AUTOSAR XML (schema 00046)
package /EcuExtract
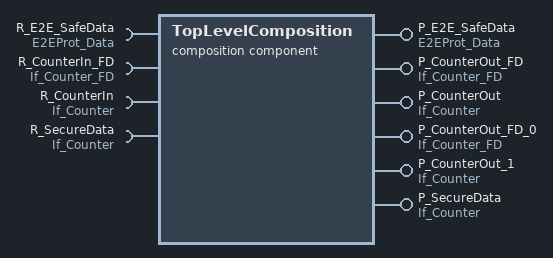
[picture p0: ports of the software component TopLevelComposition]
  composition sw component type TopLevelComposition
    provide port P_E2E_SafeData: provided-interface=E2EProt_Data
    require port R_E2E_SafeData: required-interface=E2EProt_Data
    provide port P_CounterOut_FD: provided-interface=If_Counter_FD
    provide port P_CounterOut: provided-interface=If_Counter
    provide port P_CounterOut_FD_0: provided-interface=If_Counter_FD
    require port R_CounterIn_FD: required-interface=If_Counter_FD
    provide port P_CounterOut_1: provided-interface=If_Counter
    require port R_CounterIn: required-interface=If_Counter
    provide port P_SecureData: provided-interface=If_Counter
    require port R_SecureData: required-interface=If_Counter
    17 x component:
      BswM_Prototype: type=BswM
      ComM_Prototype: type=ComM
      Dcm_Prototype: type=Dcm
      Dem_Prototype: type=Dem
      DevelopmentErrorTracer_Prototype: type=DevelopmentErrorTracer
      NvM_Prototype: type=NvM
      SWC_E2ESafety: type=SWC_E2ESafety
      SWC_SPI_Prototype: type=SWC_SPI
      SecOC_Prototype: type=SecOC
      SWC_AppStateHandler: type=SWC_AppStateHandler
      SWC_CyclicCounter: type=SWC_CyclicCounter
      SWC_IoHwAbs: type=SWC_IoHwAbs
      SWC_ModifyEcho: type=SWC_ModifyEcho
      ServiceSwComponentDcm: type=ServiceSwComponentDcm
      SWC_Secured: type=SWC_Secured
      ServiceSwComponentSecOC: type=ServiceSwComponentSecOC
      ServiceSwComponentDem: type=ServiceSwComponentDem
    connect BswM_Prototype.BswM_ModeRequestPort_BswMRteModeRequestPort_AppStateMode -> SWC_AppStateHandler.AppStateRequest
    connect SWC_AppStateHandler.AppState -> BswM_Prototype.ModeNotificationPort_BswM_ModeReqPort_AppState
    connect BswM_Prototype.BswM_ModeSwitchPort_BswM_SwitchPort_Rte -> SWC_CyclicCounter.ModeSwitchPort_BSWM_COMBINEDACTION_BswMMode_PortInterfaces_BswMMode
    connect ServiceSwComponentDcm.SecurityAccess_Level_1 -> Dcm_Prototype.SecurityAccess_Level_1
    connect ServiceSwComponentDcm.SecurityAccess_Level_3 -> Dcm_Prototype.SecurityAccess_Level_3
    connect ServiceSwComponentDcm.ServiceRequestManufacturerNotification_DcmDslServiceRequestManufacturerNotification_0 -> Dcm_Prototype.ServiceRequestManufacturerNotification_DcmDslServiceRequestManufacturerNotification_0
    connect ServiceSwComponentDcm.ServiceRequestSupplierNotification_DcmDslServiceRequestSupplierNotification_0 -> Dcm_Prototype.ServiceRequestSupplierNotification_DcmDslServiceRequestSupplierNotification_0
    connect ServiceSwComponentDcm.RoutineServices_DIAGNOSTIC_LOOPBACK -> Dcm_Prototype.RoutineServices_DIAGNOSTIC_LOOPBACK
    connect ServiceSwComponentDcm.RoutineServices_DIAGNOSTIC_TRIGGER_DTC -> Dcm_Prototype.RoutineServices_DIAGNOSTIC_TRIGGER_DTC
    connect ServiceSwComponentDcm.InfotypeServices_Service09_VinMessageCount -> Dcm_Prototype.InfotypeServices_Service09_VinMessageCount
    connect ServiceSwComponentDcm.InfotypeServices_Service09_VehicleIdentificationNumber -> Dcm_Prototype.InfotypeServices_Service09_VehicleIdentificationNumber
    connect Dem_Prototype.Event_DTC_0x000001_Event -> ServiceSwComponentDcm.DTC_0x000001_Event
    connect Dem_Prototype.Event_Permanent_DTC -> ServiceSwComponentDcm.Permanent_DTC_Event
    connect Dem_Prototype.Event_DTC_0x000002_Event -> ServiceSwComponentDcm.DTC_0x000002_Event
    connect Dem_Prototype.Event_USER_DEFINE_MEMORY_Event -> ServiceSwComponentDcm.USER_DEFINE_MEMORY_Event
    connect ServiceSwComponentDem.CBReadData_DemExternalCSDataElementClass_Session -> Dem_Prototype.CBReadData_DemExternalCSDataElementClass_Session
    connect ServiceSwComponentDem.CBReadData_DemExternalCSDataElementClass_ExtDataRec_0x01 -> Dem_Prototype.CBReadData_DemExternalCSDataElementClass_ExtDataRec_0x01
    connect ServiceSwComponentDem.SetClearDTC_master -> Dem_Prototype.SetClearDTC_master
    connect DevelopmentErrorTracer_Prototype.DS_SWC_0 -> SWC_CyclicCounter.R_CyclicCounterDet
    connect NvM_Prototype.PS_NvM_BLOCK_voltage -> SWC_SPI_Prototype.PS_NvM_Block_voltage
    connect NvM_Prototype.PS_PersistentCounterValue -> SWC_CyclicCounter.PS_PersistentCounterValue
    delegate SWC_E2ESafety.P_E2E_SafeData <-> outer port P_E2E_SafeData
    delegate SWC_E2ESafety.R_E2E_SafeData <-> outer port R_E2E_SafeData
    connect SWC_IoHwAbs.Pp_AdcValue -> SWC_SPI_Prototype.Rp_AdcValue
    connect ServiceSwComponentSecOC.PS_RxFreshnessManagement -> SecOC_Prototype.PS_RxFreshnessManagement
    connect ServiceSwComponentSecOC.PS_TxFreshnessManagement -> SecOC_Prototype.PS_TxFreshnessManagement
    delegate SWC_CyclicCounter.P_CounterOut_FD <-> outer port P_CounterOut_FD
    connect SWC_CyclicCounter.P_EchoCalc_FD -> SWC_ModifyEcho.R_EchoResult_FD
    connect SWC_CyclicCounter.P_EchoCalc -> SWC_ModifyEcho.R_EchoResult
    connect SWC_ModifyEcho.P_SpecialRequest -> SWC_CyclicCounter.R_SpecialHandling
    connect SWC_IoHwAbs.P_MyLED -> SWC_CyclicCounter.R_MyLED
    delegate SWC_CyclicCounter.P_CounterOut <-> outer port P_CounterOut
    delegate SWC_ModifyEcho.P_EchoOut_FD <-> outer port P_CounterOut_FD_0
    delegate SWC_ModifyEcho.R_NewCounterIn_FD <-> outer port R_CounterIn_FD
    delegate SWC_ModifyEcho.P_EchoOut <-> outer port P_CounterOut_1
    delegate SWC_ModifyEcho.R_NewCounterIn <-> outer port R_CounterIn
    delegate SWC_Secured.P_SecuredData <-> outer port P_SecureData
    delegate SWC_Secured.R_SecuredData <-> outer port R_SecureData
  system ECU: category=ECU_EXTRACT, system-version=1.0.0
    10 x system mapping:
      DataMappings_P_E2E_SafeData: sender-receiver-to-signal-group-mapping{data-element=TopLevelCompositionPrototype.P_E2E_SafeData.E2EProt_Data, signal-group=sigGroup_E2EProt_DataOut, type-mapping=sender-rec-record-type-mapping=record-element-mappings=[{implementation-record-element=SafetyE2E_Data, system-signal=SysSig_E2EProt_DataOut}, {implementation-record-element=SafetyE2E_Data_CRC, system-signal=SysSig_E2EProt_DataOut_CRC}, {implementation-record-element=SafetyE2E_Data_SQC_Counter, system-signal=SysSig_E2EProt_DataOut_SQC_Counter}]}
      DataMappings_R_E2E_SafeData: sender-receiver-to-signal-group-mapping{data-element=TopLevelCompositionPrototype.R_E2E_SafeData.E2EProt_Data, signal-group=sigGroup_E2EProt_DataIn, type-mapping=sender-rec-record-type-mapping=record-element-mappings=[{implementation-record-element=SafetyE2E_Data, system-signal=SysSig_E2EProt_DataIn}, {implementation-record-element=SafetyE2E_Data_CRC, system-signal=SysSig_E2EProt_DataIn_CRC}, {implementation-record-element=SafetyE2E_Data_SQC_Counter, system-signal=SysSig_E2EProt_DataIn_SQC_Counter}]}
      DataMappings_P_CounterOut_FD: sender-receiver-to-signal-mapping{data-element=TopLevelCompositionPrototype.P_CounterOut_FD.CounterValue_FD, system-signal=CounterOut_CAN_FD}
      DataMappings_P_CounterOut: sender-receiver-to-signal-mapping{data-element=TopLevelCompositionPrototype.P_CounterOut.CounterValue, system-signal=CounterOut}
      DataMappings_P_CounterOut_FD_0: sender-receiver-to-signal-mapping{data-element=TopLevelCompositionPrototype.P_CounterOut_FD_0.CounterValue_FD, system-signal=CounterOut_CAN_FD}
      DataMappings_R_CounterIn_FD: sender-receiver-to-signal-mapping{data-element=TopLevelCompositionPrototype.R_CounterIn_FD.CounterValue_FD, system-signal=CounterIn_CAN_FD}
      DataMappings_P_CounterOut_1: sender-receiver-to-signal-mapping{data-element=TopLevelCompositionPrototype.P_CounterOut_1.CounterValue, system-signal=CounterOut}
      DataMappings_R_CounterIn: sender-receiver-to-signal-mapping{data-element=TopLevelCompositionPrototype.R_CounterIn.CounterValue, system-signal=CounterIn}
      DataMappings_P_SecureData
        data-mappings:
          data-element=TopLevelCompositionPrototype.P_SecureData.CounterValue, system-signal=SecuredDataOut
          data-element=TopLevelCompositionPrototype.P_SecureData.CounterValue, system-signal=SecuredDataIn
      DataMappings_R_SecureData
        data-mappings:
          data-element=TopLevelCompositionPrototype.R_SecureData.CounterValue, system-signal=SecuredDataIn
          data-element=TopLevelCompositionPrototype.R_SecureData.CounterValue, system-signal=SecuredDataOut
    root-software-compositions:
      root sw composition prototype TopLevelCompositionPrototype: flat-map=FlatMap, software-composition=TopLevelComposition
  flat map FlatMap
    137 x flat instance descriptor:
      BswM_Prototype_0: upstream-reference=TopLevelComposition.BswM_Prototype, ecu-extract-reference=TopLevelCompositionPrototype.BswM_Prototype
      BswM_ModeSwitchPort_BswM_SwitchPort_Rte_1: upstream-reference=TopLevelComposition.BswM_Prototype.BswM_ModeSwitchPort_BswM_SwitchPort_Rte, ecu-extract-reference=TopLevelCompositionPrototype.BswM_Prototype.BswM_ModeSwitchPort_BswM_SwitchPort_Rte
      BswM_ModeRequestPort_BswMRteModeRequestPort_AppStateMode_2: upstream-reference=TopLevelComposition.BswM_Prototype.BswM_ModeRequestPort_BswMRteModeRequestPort_AppStateMode, ecu-extract-reference=TopLevelCompositionPrototype.BswM_Prototype.BswM_ModeRequestPort_BswMRteModeRequestPort_AppStateMode
      If_AppStateRequestMode_3: upstream-reference=TopLevelComposition.BswM_Prototype.BswM_ModeRequestPort_BswMRteModeRequestPort_AppStateMode.If_AppStateRequestMode, ecu-extract-reference=TopLevelCompositionPrototype.BswM_Prototype.BswM_ModeRequestPort_BswMRteModeRequestPort_AppStateMode.If_AppStateRequestMode
      ModeNotificationPort_BswM_ModeReqPort_AppState_4: upstream-reference=TopLevelComposition.BswM_Prototype.ModeNotificationPort_BswM_ModeReqPort_AppState, ecu-extract-reference=TopLevelCompositionPrototype.BswM_Prototype.ModeNotificationPort_BswM_ModeReqPort_AppState
      ComM_Prototype_5: upstream-reference=TopLevelComposition.ComM_Prototype, ecu-extract-reference=TopLevelCompositionPrototype.ComM_Prototype
      UM_ComMUser_0_6: upstream-reference=TopLevelComposition.ComM_Prototype.UM_ComMUser_0, ecu-extract-reference=TopLevelCompositionPrototype.ComM_Prototype.UM_ComMUser_0
      UR_ComMUser_0_7: upstream-reference=TopLevelComposition.ComM_Prototype.UR_ComMUser_0, ecu-extract-reference=TopLevelCompositionPrototype.ComM_Prototype.UR_ComMUser_0
      Dcm_Prototype_8: upstream-reference=TopLevelComposition.Dcm_Prototype, ecu-extract-reference=TopLevelCompositionPrototype.Dcm_Prototype
      DCMServices_9: upstream-reference=TopLevelComposition.Dcm_Prototype.DCMServices, ecu-extract-reference=TopLevelCompositionPrototype.Dcm_Prototype.DCMServices
      DCM_Roe_DcmDspRoeEvent_10: upstream-reference=TopLevelComposition.Dcm_Prototype.DCM_Roe_DcmDspRoeEvent, ecu-extract-reference=TopLevelCompositionPrototype.Dcm_Prototype.DCM_Roe_DcmDspRoeEvent
      SecurityAccess_Level_1_11: upstream-reference=TopLevelComposition.Dcm_Prototype.SecurityAccess_Level_1, ecu-extract-reference=TopLevelCompositionPrototype.Dcm_Prototype.SecurityAccess_Level_1
      SecurityAccess_Level_3_12: upstream-reference=TopLevelComposition.Dcm_Prototype.SecurityAccess_Level_3, ecu-extract-reference=TopLevelCompositionPrototype.Dcm_Prototype.SecurityAccess_Level_3
      ServiceRequestManufacturerNotification_DcmDslServiceRequestManufacturerNotification_0_13: upstream-reference=TopLevelComposition.Dcm_Prototype.ServiceRequestManufacturerNotification_DcmDslServiceRequestManufacturerNotification_0, ecu-extract-reference=TopLevelCompositionPrototype.Dcm_Prototype.ServiceRequestManufacturerNotification_DcmDslServiceRequestManufacturerNotification_0
      ServiceRequestSupplierNotification_DcmDslServiceRequestSupplierNotification_0_14: upstream-reference=TopLevelComposition.Dcm_Prototype.ServiceRequestSupplierNotification_DcmDslServiceRequestSupplierNotification_0, ecu-extract-reference=TopLevelCompositionPrototype.Dcm_Prototype.ServiceRequestSupplierNotification_DcmDslServiceRequestSupplierNotification_0
      RoutineServices_DIAGNOSTIC_LOOPBACK_15: upstream-reference=TopLevelComposition.Dcm_Prototype.RoutineServices_DIAGNOSTIC_LOOPBACK, ecu-extract-reference=TopLevelCompositionPrototype.Dcm_Prototype.RoutineServices_DIAGNOSTIC_LOOPBACK
      RoutineServices_DIAGNOSTIC_TRIGGER_DTC_16: upstream-reference=TopLevelComposition.Dcm_Prototype.RoutineServices_DIAGNOSTIC_TRIGGER_DTC, ecu-extract-reference=TopLevelCompositionPrototype.Dcm_Prototype.RoutineServices_DIAGNOSTIC_TRIGGER_DTC
      InfotypeServices_Service09_VinMessageCount_17: upstream-reference=TopLevelComposition.Dcm_Prototype.InfotypeServices_Service09_VinMessageCount, ecu-extract-reference=TopLevelCompositionPrototype.Dcm_Prototype.InfotypeServices_Service09_VinMessageCount
      InfotypeServices_Service09_VehicleIdentificationNumber_18: upstream-reference=TopLevelComposition.Dcm_Prototype.InfotypeServices_Service09_VehicleIdentificationNumber, ecu-extract-reference=TopLevelCompositionPrototype.Dcm_Prototype.InfotypeServices_Service09_VehicleIdentificationNumber
      Dem_Prototype_19: upstream-reference=TopLevelComposition.Dem_Prototype, ecu-extract-reference=TopLevelCompositionPrototype.Dem_Prototype
      Event_DTC_0x000001_Event_20: upstream-reference=TopLevelComposition.Dem_Prototype.Event_DTC_0x000001_Event, ecu-extract-reference=TopLevelCompositionPrototype.Dem_Prototype.Event_DTC_0x000001_Event
      EvtInfo_DTC_0x000001_Event_21: upstream-reference=TopLevelComposition.Dem_Prototype.EvtInfo_DTC_0x000001_Event, ecu-extract-reference=TopLevelCompositionPrototype.Dem_Prototype.EvtInfo_DTC_0x000001_Event
      Event_Permanent_DTC_22: upstream-reference=TopLevelComposition.Dem_Prototype.Event_Permanent_DTC, ecu-extract-reference=TopLevelCompositionPrototype.Dem_Prototype.Event_Permanent_DTC
      EvtInfo_Permanent_DTC_23: upstream-reference=TopLevelComposition.Dem_Prototype.EvtInfo_Permanent_DTC, ecu-extract-reference=TopLevelCompositionPrototype.Dem_Prototype.EvtInfo_Permanent_DTC
      EvtInfo_CANSM_E_BUS_OFF_0_24: upstream-reference=TopLevelComposition.Dem_Prototype.EvtInfo_CANSM_E_BUS_OFF_0, ecu-extract-reference=TopLevelCompositionPrototype.Dem_Prototype.EvtInfo_CANSM_E_BUS_OFF_0
      EvtInfo_WDGM_E_MONITORING_25: upstream-reference=TopLevelComposition.Dem_Prototype.EvtInfo_WDGM_E_MONITORING, ecu-extract-reference=TopLevelCompositionPrototype.Dem_Prototype.EvtInfo_WDGM_E_MONITORING
      EvtInfo_WDGM_E_SET_MODE_26: upstream-reference=TopLevelComposition.Dem_Prototype.EvtInfo_WDGM_E_SET_MODE, ecu-extract-reference=TopLevelCompositionPrototype.Dem_Prototype.EvtInfo_WDGM_E_SET_MODE
      EvtInfo_WDGM_E_DATA_CORRUPTION_27: upstream-reference=TopLevelComposition.Dem_Prototype.EvtInfo_WDGM_E_DATA_CORRUPTION, ecu-extract-reference=TopLevelCompositionPrototype.Dem_Prototype.EvtInfo_WDGM_E_DATA_CORRUPTION
      EvtInfo_ECUM_E_RAM_CHECK_FAILED_28: upstream-reference=TopLevelComposition.Dem_Prototype.EvtInfo_ECUM_E_RAM_CHECK_FAILED, ecu-extract-reference=TopLevelCompositionPrototype.Dem_Prototype.EvtInfo_ECUM_E_RAM_CHECK_FAILED
      EvtInfo_MCU_E_CLOCK_FAILURE_29: upstream-reference=TopLevelComposition.Dem_Prototype.EvtInfo_MCU_E_CLOCK_FAILURE, ecu-extract-reference=TopLevelCompositionPrototype.Dem_Prototype.EvtInfo_MCU_E_CLOCK_FAILURE
      EvtInfo_WDGM_E_MF_TIMINGVIOLATION_30: upstream-reference=TopLevelComposition.Dem_Prototype.EvtInfo_WDGM_E_MF_TIMINGVIOLATION, ecu-extract-reference=TopLevelCompositionPrototype.Dem_Prototype.EvtInfo_WDGM_E_MF_TIMINGVIOLATION
      Event_DTC_0x000002_Event_31: upstream-reference=TopLevelComposition.Dem_Prototype.Event_DTC_0x000002_Event, ecu-extract-reference=TopLevelCompositionPrototype.Dem_Prototype.Event_DTC_0x000002_Event
      EvtInfo_DTC_0x000002_Event_32: upstream-reference=TopLevelComposition.Dem_Prototype.EvtInfo_DTC_0x000002_Event, ecu-extract-reference=TopLevelCompositionPrototype.Dem_Prototype.EvtInfo_DTC_0x000002_Event
      Event_USER_DEFINE_MEMORY_Event_33: upstream-reference=TopLevelComposition.Dem_Prototype.Event_USER_DEFINE_MEMORY_Event, ecu-extract-reference=TopLevelCompositionPrototype.Dem_Prototype.Event_USER_DEFINE_MEMORY_Event
      EvtInfo_USER_DEFINE_MEMORY_Event_34: upstream-reference=TopLevelComposition.Dem_Prototype.EvtInfo_USER_DEFINE_MEMORY_Event, ecu-extract-reference=TopLevelCompositionPrototype.Dem_Prototype.EvtInfo_USER_DEFINE_MEMORY_Event
      EvtInfo_MCU_E_TIMEOUT_FAILURE_35: upstream-reference=TopLevelComposition.Dem_Prototype.EvtInfo_MCU_E_TIMEOUT_FAILURE, ecu-extract-reference=TopLevelCompositionPrototype.Dem_Prototype.EvtInfo_MCU_E_TIMEOUT_FAILURE
      EvtInfo_MCU_E_INVALIDFXOSC_CONFIG_36: upstream-reference=TopLevelComposition.Dem_Prototype.EvtInfo_MCU_E_INVALIDFXOSC_CONFIG, ecu-extract-reference=TopLevelCompositionPrototype.Dem_Prototype.EvtInfo_MCU_E_INVALIDFXOSC_CONFIG
      EvtInfo_MCU_E_CLOCKMUXSWITCH_FAILURE_37: upstream-reference=TopLevelComposition.Dem_Prototype.EvtInfo_MCU_E_CLOCKMUXSWITCH_FAILURE, ecu-extract-reference=TopLevelCompositionPrototype.Dem_Prototype.EvtInfo_MCU_E_CLOCKMUXSWITCH_FAILURE
      EvtInfo_SPI_E_HARDWARE_ERROR_38: upstream-reference=TopLevelComposition.Dem_Prototype.EvtInfo_SPI_E_HARDWARE_ERROR, ecu-extract-reference=TopLevelCompositionPrototype.Dem_Prototype.EvtInfo_SPI_E_HARDWARE_ERROR
      GeneralEvtInfo_39: upstream-reference=TopLevelComposition.Dem_Prototype.GeneralEvtInfo, ecu-extract-reference=TopLevelCompositionPrototype.Dem_Prototype.GeneralEvtInfo
      OpCycle_DEM_OPCYC_IGNITION_40: upstream-reference=TopLevelComposition.Dem_Prototype.OpCycle_DEM_OPCYC_IGNITION, ecu-extract-reference=TopLevelCompositionPrototype.Dem_Prototype.OpCycle_DEM_OPCYC_IGNITION
      OpCycle_DEM_OPCYC_OBD_DCY_41: upstream-reference=TopLevelComposition.Dem_Prototype.OpCycle_DEM_OPCYC_OBD_DCY, ecu-extract-reference=TopLevelCompositionPrototype.Dem_Prototype.OpCycle_DEM_OPCYC_OBD_DCY
      OpCycle_DEM_OPCYC_POWER_42: upstream-reference=TopLevelComposition.Dem_Prototype.OpCycle_DEM_OPCYC_POWER, ecu-extract-reference=TopLevelCompositionPrototype.Dem_Prototype.OpCycle_DEM_OPCYC_POWER
      EnableCond_DEM_SL_ECU_LEVEL_43: upstream-reference=TopLevelComposition.Dem_Prototype.EnableCond_DEM_SL_ECU_LEVEL, ecu-extract-reference=TopLevelCompositionPrototype.Dem_Prototype.EnableCond_DEM_SL_ECU_LEVEL
      IndStatus_DEM_INDICATOR_0_44: upstream-reference=TopLevelComposition.Dem_Prototype.IndStatus_DEM_INDICATOR_0, ecu-extract-reference=TopLevelCompositionPrototype.Dem_Prototype.IndStatus_DEM_INDICATOR_0
      OverflowIndPrimaryMemory_45: upstream-reference=TopLevelComposition.Dem_Prototype.OverflowIndPrimaryMemory, ecu-extract-reference=TopLevelCompositionPrototype.Dem_Prototype.OverflowIndPrimaryMemory
      OverflowIndSecondaryMemory_46: upstream-reference=TopLevelComposition.Dem_Prototype.OverflowIndSecondaryMemory, ecu-extract-reference=TopLevelCompositionPrototype.Dem_Prototype.OverflowIndSecondaryMemory
      OverflowIndPermanentMemory_47: upstream-reference=TopLevelComposition.Dem_Prototype.OverflowIndPermanentMemory, ecu-extract-reference=TopLevelCompositionPrototype.Dem_Prototype.OverflowIndPermanentMemory
      ControlDTCSuppression_48: upstream-reference=TopLevelComposition.Dem_Prototype.ControlDTCSuppression, ecu-extract-reference=TopLevelCompositionPrototype.Dem_Prototype.ControlDTCSuppression
      CddIf_49: upstream-reference=TopLevelComposition.Dem_Prototype.CddIf, ecu-extract-reference=TopLevelCompositionPrototype.Dem_Prototype.CddIf
      PfcCycleQualified_50: upstream-reference=TopLevelComposition.Dem_Prototype.PfcCycleQualified, ecu-extract-reference=TopLevelCompositionPrototype.Dem_Prototype.PfcCycleQualified
      ResetReadiness_51: upstream-reference=TopLevelComposition.Dem_Prototype.ResetReadiness, ecu-extract-reference=TopLevelCompositionPrototype.Dem_Prototype.ResetReadiness
      PowerTakeOffStatus_52: upstream-reference=TopLevelComposition.Dem_Prototype.PowerTakeOffStatus, ecu-extract-reference=TopLevelCompositionPrototype.Dem_Prototype.PowerTakeOffStatus
      CBReadData_DemExternalCSDataElementClass_Session_53: upstream-reference=TopLevelComposition.Dem_Prototype.CBReadData_DemExternalCSDataElementClass_Session, ecu-extract-reference=TopLevelCompositionPrototype.Dem_Prototype.CBReadData_DemExternalCSDataElementClass_Session
      CBReadData_DemExternalCSDataElementClass_ExtDataRec_0x01_54: upstream-reference=TopLevelComposition.Dem_Prototype.CBReadData_DemExternalCSDataElementClass_ExtDataRec_0x01, ecu-extract-reference=TopLevelCompositionPrototype.Dem_Prototype.CBReadData_DemExternalCSDataElementClass_ExtDataRec_0x01
      SetClearDTC_master_55: upstream-reference=TopLevelComposition.Dem_Prototype.SetClearDTC_master, ecu-extract-reference=TopLevelCompositionPrototype.Dem_Prototype.SetClearDTC_master
      DevelopmentErrorTracer_Prototype_56: upstream-reference=TopLevelComposition.DevelopmentErrorTracer_Prototype, ecu-extract-reference=TopLevelCompositionPrototype.DevelopmentErrorTracer_Prototype
      DS_SWC_0_57: upstream-reference=TopLevelComposition.DevelopmentErrorTracer_Prototype.DS_SWC_0, ecu-extract-reference=TopLevelCompositionPrototype.DevelopmentErrorTracer_Prototype.DS_SWC_0
      NvM_Prototype_58: upstream-reference=TopLevelComposition.NvM_Prototype, ecu-extract-reference=TopLevelCompositionPrototype.NvM_Prototype
      PS_PersistentCounterValue_59: upstream-reference=TopLevelComposition.NvM_Prototype.PS_PersistentCounterValue, ecu-extract-reference=TopLevelCompositionPrototype.NvM_Prototype.PS_PersistentCounterValue
      PS_NvM_BLOCK_voltage_60: upstream-reference=TopLevelComposition.NvM_Prototype.PS_NvM_BLOCK_voltage, ecu-extract-reference=TopLevelCompositionPrototype.NvM_Prototype.PS_NvM_BLOCK_voltage
      SWC_E2ESafety_61: upstream-reference=TopLevelComposition.SWC_E2ESafety, ecu-extract-reference=TopLevelCompositionPrototype.SWC_E2ESafety
      P_E2E_SafeData_62: upstream-reference=TopLevelComposition.SWC_E2ESafety.P_E2E_SafeData, ecu-extract-reference=TopLevelCompositionPrototype.SWC_E2ESafety.P_E2E_SafeData
      E2EProt_Data_63: upstream-reference=TopLevelComposition.SWC_E2ESafety.P_E2E_SafeData.E2EProt_Data, ecu-extract-reference=TopLevelCompositionPrototype.SWC_E2ESafety.P_E2E_SafeData.E2EProt_Data
      R_E2E_SafeData_64: upstream-reference=TopLevelComposition.SWC_E2ESafety.R_E2E_SafeData, ecu-extract-reference=TopLevelCompositionPrototype.SWC_E2ESafety.R_E2E_SafeData
      E2EProt_Data_65: upstream-reference=TopLevelComposition.SWC_E2ESafety.R_E2E_SafeData.E2EProt_Data, ecu-extract-reference=TopLevelCompositionPrototype.SWC_E2ESafety.R_E2E_SafeData.E2EProt_Data
      SWC_SPI_Prototype_66: upstream-reference=TopLevelComposition.SWC_SPI_Prototype, ecu-extract-reference=TopLevelCompositionPrototype.SWC_SPI_Prototype
      PS_NvM_Block_voltage_67: upstream-reference=TopLevelComposition.SWC_SPI_Prototype.PS_NvM_Block_voltage, ecu-extract-reference=TopLevelCompositionPrototype.SWC_SPI_Prototype.PS_NvM_Block_voltage
      Rp_AdcValue_68: upstream-reference=TopLevelComposition.SWC_SPI_Prototype.Rp_AdcValue, ecu-extract-reference=TopLevelCompositionPrototype.SWC_SPI_Prototype.Rp_AdcValue
      ArgData_69: upstream-reference=TopLevelComposition.SWC_SPI_Prototype.Rp_AdcValue.ArgData, ecu-extract-reference=TopLevelCompositionPrototype.SWC_SPI_Prototype.Rp_AdcValue.ArgData
      SecOC_Prototype_70: upstream-reference=TopLevelComposition.SecOC_Prototype, ecu-extract-reference=TopLevelCompositionPrototype.SecOC_Prototype
      PS_RxFreshnessManagement_71: upstream-reference=TopLevelComposition.SecOC_Prototype.PS_RxFreshnessManagement, ecu-extract-reference=TopLevelCompositionPrototype.SecOC_Prototype.PS_RxFreshnessManagement
      PS_VerifyStatusConfiguration_72: upstream-reference=TopLevelComposition.SecOC_Prototype.PS_VerifyStatusConfiguration, ecu-extract-reference=TopLevelCompositionPrototype.SecOC_Prototype.PS_VerifyStatusConfiguration
      PS_TxFreshnessManagement_73: upstream-reference=TopLevelComposition.SecOC_Prototype.PS_TxFreshnessManagement, ecu-extract-reference=TopLevelCompositionPrototype.SecOC_Prototype.PS_TxFreshnessManagement
      SWC_AppStateHandler_74: upstream-reference=TopLevelComposition.SWC_AppStateHandler, ecu-extract-reference=TopLevelCompositionPrototype.SWC_AppStateHandler
      AppState_75: upstream-reference=TopLevelComposition.SWC_AppStateHandler.AppState, ecu-extract-reference=TopLevelCompositionPrototype.SWC_AppStateHandler.AppState
      AppStateRequest_76: upstream-reference=TopLevelComposition.SWC_AppStateHandler.AppStateRequest, ecu-extract-reference=TopLevelCompositionPrototype.SWC_AppStateHandler.AppStateRequest
      If_AppStateRequestMode_77: upstream-reference=TopLevelComposition.SWC_AppStateHandler.AppStateRequest.If_AppStateRequestMode, ecu-extract-reference=TopLevelCompositionPrototype.SWC_AppStateHandler.AppStateRequest.If_AppStateRequestMode
      SWC_CyclicCounter_78: upstream-reference=TopLevelComposition.SWC_CyclicCounter, ecu-extract-reference=TopLevelCompositionPrototype.SWC_CyclicCounter
      ModeSwitchPort_BSWM_COMBINEDACTION_BswMMode_PortInterfaces_BswMMode_79: upstream-reference=TopLevelComposition.SWC_CyclicCounter.ModeSwitchPort_BSWM_COMBINEDACTION_BswMMode_PortInterfaces_BswMMode, ecu-extract-reference=TopLevelCompositionPrototype.SWC_CyclicCounter.ModeSwitchPort_BSWM_COMBINEDACTION_BswMMode_PortInterfaces_BswMMode
      PS_PersistentCounterValue_80: upstream-reference=TopLevelComposition.SWC_CyclicCounter.PS_PersistentCounterValue, ecu-extract-reference=TopLevelCompositionPrototype.SWC_CyclicCounter.PS_PersistentCounterValue
      P_CounterOut_81: upstream-reference=TopLevelComposition.SWC_CyclicCounter.P_CounterOut, ecu-extract-reference=TopLevelCompositionPrototype.SWC_CyclicCounter.P_CounterOut
      CounterValue_82: upstream-reference=TopLevelComposition.SWC_CyclicCounter.P_CounterOut.CounterValue, ecu-extract-reference=TopLevelCompositionPrototype.SWC_CyclicCounter.P_CounterOut.CounterValue
      P_CounterOut_FD_83: upstream-reference=TopLevelComposition.SWC_CyclicCounter.P_CounterOut_FD, ecu-extract-reference=TopLevelCompositionPrototype.SWC_CyclicCounter.P_CounterOut_FD
      CounterValue_FD_84: upstream-reference=TopLevelComposition.SWC_CyclicCounter.P_CounterOut_FD.CounterValue_FD, ecu-extract-reference=TopLevelCompositionPrototype.SWC_CyclicCounter.P_CounterOut_FD.CounterValue_FD
      P_EchoCalc_85: upstream-reference=TopLevelComposition.SWC_CyclicCounter.P_EchoCalc, ecu-extract-reference=TopLevelCompositionPrototype.SWC_CyclicCounter.P_EchoCalc
      P_EchoCalc_FD_86: upstream-reference=TopLevelComposition.SWC_CyclicCounter.P_EchoCalc_FD, ecu-extract-reference=TopLevelCompositionPrototype.SWC_CyclicCounter.P_EchoCalc_FD
      R_CyclicCounterDet_87: upstream-reference=TopLevelComposition.SWC_CyclicCounter.R_CyclicCounterDet, ecu-extract-reference=TopLevelCompositionPrototype.SWC_CyclicCounter.R_CyclicCounterDet
      R_MyLED_88: upstream-reference=TopLevelComposition.SWC_CyclicCounter.R_MyLED, ecu-extract-reference=TopLevelCompositionPrototype.SWC_CyclicCounter.R_MyLED
      R_SpecialHandling_89: upstream-reference=TopLevelComposition.SWC_CyclicCounter.R_SpecialHandling, ecu-extract-reference=TopLevelCompositionPrototype.SWC_CyclicCounter.R_SpecialHandling
      EventMessage_90: upstream-reference=TopLevelComposition.SWC_CyclicCounter.R_SpecialHandling.EventMessage, ecu-extract-reference=TopLevelCompositionPrototype.SWC_CyclicCounter.R_SpecialHandling.EventMessage
      UR_ComMUser_0_91: upstream-reference=TopLevelComposition.SWC_CyclicCounter.UR_ComMUser_0, ecu-extract-reference=TopLevelCompositionPrototype.SWC_CyclicCounter.UR_ComMUser_0
      CurrentCounterValue_92: upstream-reference=TopLevelComposition.SWC_CyclicCounter.CurrentCounterValue, ecu-extract-reference=TopLevelCompositionPrototype.SWC_CyclicCounter.CurrentCounterValue
      CurrentCounterValue_FD_93: upstream-reference=TopLevelComposition.SWC_CyclicCounter.CurrentCounterValue_FD, ecu-extract-reference=TopLevelCompositionPrototype.SWC_CyclicCounter.CurrentCounterValue_FD
      PrmCounterValue_94: upstream-reference=TopLevelComposition.SWC_CyclicCounter.PrmCounterValue, ecu-extract-reference=TopLevelCompositionPrototype.SWC_CyclicCounter.PrmCounterValue
      SWC_IoHwAbs_95: upstream-reference=TopLevelComposition.SWC_IoHwAbs, ecu-extract-reference=TopLevelCompositionPrototype.SWC_IoHwAbs
      P_MyLED_96: upstream-reference=TopLevelComposition.SWC_IoHwAbs.P_MyLED, ecu-extract-reference=TopLevelCompositionPrototype.SWC_IoHwAbs.P_MyLED
      Pp_AdcValue_97: upstream-reference=TopLevelComposition.SWC_IoHwAbs.Pp_AdcValue, ecu-extract-reference=TopLevelCompositionPrototype.SWC_IoHwAbs.Pp_AdcValue
      ArgData_98: upstream-reference=TopLevelComposition.SWC_IoHwAbs.Pp_AdcValue.ArgData, ecu-extract-reference=TopLevelCompositionPrototype.SWC_IoHwAbs.Pp_AdcValue.ArgData
      SWC_ModifyEcho_99: upstream-reference=TopLevelComposition.SWC_ModifyEcho, ecu-extract-reference=TopLevelCompositionPrototype.SWC_ModifyEcho
      P_EchoOut_100: upstream-reference=TopLevelComposition.SWC_ModifyEcho.P_EchoOut, ecu-extract-reference=TopLevelCompositionPrototype.SWC_ModifyEcho.P_EchoOut
      CounterValue_101: upstream-reference=TopLevelComposition.SWC_ModifyEcho.P_EchoOut.CounterValue, ecu-extract-reference=TopLevelCompositionPrototype.SWC_ModifyEcho.P_EchoOut.CounterValue
      P_EchoOut_FD_102: upstream-reference=TopLevelComposition.SWC_ModifyEcho.P_EchoOut_FD, ecu-extract-reference=TopLevelCompositionPrototype.SWC_ModifyEcho.P_EchoOut_FD
      CounterValue_FD_103: upstream-reference=TopLevelComposition.SWC_ModifyEcho.P_EchoOut_FD.CounterValue_FD, ecu-extract-reference=TopLevelCompositionPrototype.SWC_ModifyEcho.P_EchoOut_FD.CounterValue_FD
      P_SpecialRequest_104: upstream-reference=TopLevelComposition.SWC_ModifyEcho.P_SpecialRequest, ecu-extract-reference=TopLevelCompositionPrototype.SWC_ModifyEcho.P_SpecialRequest
      EventMessage_105: upstream-reference=TopLevelComposition.SWC_ModifyEcho.P_SpecialRequest.EventMessage, ecu-extract-reference=TopLevelCompositionPrototype.SWC_ModifyEcho.P_SpecialRequest.EventMessage
      R_EchoResult_106: upstream-reference=TopLevelComposition.SWC_ModifyEcho.R_EchoResult, ecu-extract-reference=TopLevelCompositionPrototype.SWC_ModifyEcho.R_EchoResult
      R_EchoResult_FD_107: upstream-reference=TopLevelComposition.SWC_ModifyEcho.R_EchoResult_FD, ecu-extract-reference=TopLevelCompositionPrototype.SWC_ModifyEcho.R_EchoResult_FD
      R_NewCounterIn_108: upstream-reference=TopLevelComposition.SWC_ModifyEcho.R_NewCounterIn, ecu-extract-reference=TopLevelCompositionPrototype.SWC_ModifyEcho.R_NewCounterIn
      CounterValue_109: upstream-reference=TopLevelComposition.SWC_ModifyEcho.R_NewCounterIn.CounterValue, ecu-extract-reference=TopLevelCompositionPrototype.SWC_ModifyEcho.R_NewCounterIn.CounterValue
      R_NewCounterIn_FD_110: upstream-reference=TopLevelComposition.SWC_ModifyEcho.R_NewCounterIn_FD, ecu-extract-reference=TopLevelCompositionPrototype.SWC_ModifyEcho.R_NewCounterIn_FD
      CounterValue_FD_111: upstream-reference=TopLevelComposition.SWC_ModifyEcho.R_NewCounterIn_FD.CounterValue_FD, ecu-extract-reference=TopLevelCompositionPrototype.SWC_ModifyEcho.R_NewCounterIn_FD.CounterValue_FD
      ServiceSwComponentDcm_112: upstream-reference=TopLevelComposition.ServiceSwComponentDcm, ecu-extract-reference=TopLevelCompositionPrototype.ServiceSwComponentDcm
      DTC_0x000001_Event_113: upstream-reference=TopLevelComposition.ServiceSwComponentDcm.DTC_0x000001_Event, ecu-extract-reference=TopLevelCompositionPrototype.ServiceSwComponentDcm.DTC_0x000001_Event
      DTC_0x000002_Event_114: upstream-reference=TopLevelComposition.ServiceSwComponentDcm.DTC_0x000002_Event, ecu-extract-reference=TopLevelCompositionPrototype.ServiceSwComponentDcm.DTC_0x000002_Event
      Permanent_DTC_Event_115: upstream-reference=TopLevelComposition.ServiceSwComponentDcm.Permanent_DTC_Event, ecu-extract-reference=TopLevelCompositionPrototype.ServiceSwComponentDcm.Permanent_DTC_Event
      USER_DEFINE_MEMORY_Event_116: upstream-reference=TopLevelComposition.ServiceSwComponentDcm.USER_DEFINE_MEMORY_Event, ecu-extract-reference=TopLevelCompositionPrototype.ServiceSwComponentDcm.USER_DEFINE_MEMORY_Event
      SecurityAccess_Level_1_117: upstream-reference=TopLevelComposition.ServiceSwComponentDcm.SecurityAccess_Level_1, ecu-extract-reference=TopLevelCompositionPrototype.ServiceSwComponentDcm.SecurityAccess_Level_1
      SecurityAccess_Level_3_118: upstream-reference=TopLevelComposition.ServiceSwComponentDcm.SecurityAccess_Level_3, ecu-extract-reference=TopLevelCompositionPrototype.ServiceSwComponentDcm.SecurityAccess_Level_3
      ServiceRequestManufacturerNotification_DcmDslServiceRequestManufacturerNotification_0_119: upstream-reference=TopLevelComposition.ServiceSwComponentDcm.ServiceRequestManufacturerNotification_DcmDslServiceRequestManufacturerNotification_0, ecu-extract-reference=TopLevelCompositionPrototype.ServiceSwComponentDcm.ServiceRequestManufacturerNotification_DcmDslServiceRequestManufacturerNotification_0
      ServiceRequestSupplierNotification_DcmDslServiceRequestSupplierNotification_0_120: upstream-reference=TopLevelComposition.ServiceSwComponentDcm.ServiceRequestSupplierNotification_DcmDslServiceRequestSupplierNotification_0, ecu-extract-reference=TopLevelCompositionPrototype.ServiceSwComponentDcm.ServiceRequestSupplierNotification_DcmDslServiceRequestSupplierNotification_0
      RoutineServices_DIAGNOSTIC_LOOPBACK_121: upstream-reference=TopLevelComposition.ServiceSwComponentDcm.RoutineServices_DIAGNOSTIC_LOOPBACK, ecu-extract-reference=TopLevelCompositionPrototype.ServiceSwComponentDcm.RoutineServices_DIAGNOSTIC_LOOPBACK
      RoutineServices_DIAGNOSTIC_TRIGGER_DTC_122: upstream-reference=TopLevelComposition.ServiceSwComponentDcm.RoutineServices_DIAGNOSTIC_TRIGGER_DTC, ecu-extract-reference=TopLevelCompositionPrototype.ServiceSwComponentDcm.RoutineServices_DIAGNOSTIC_TRIGGER_DTC
      InfotypeServices_Service09_VinMessageCount_123: upstream-reference=TopLevelComposition.ServiceSwComponentDcm.InfotypeServices_Service09_VinMessageCount, ecu-extract-reference=TopLevelCompositionPrototype.ServiceSwComponentDcm.InfotypeServices_Service09_VinMessageCount
      InfotypeServices_Service09_VehicleIdentificationNumber_124: upstream-reference=TopLevelComposition.ServiceSwComponentDcm.InfotypeServices_Service09_VehicleIdentificationNumber, ecu-extract-reference=TopLevelCompositionPrototype.ServiceSwComponentDcm.InfotypeServices_Service09_VehicleIdentificationNumber
      SWC_Secured_125: upstream-reference=TopLevelComposition.SWC_Secured, ecu-extract-reference=TopLevelCompositionPrototype.SWC_Secured
      P_SecuredData_126: upstream-reference=TopLevelComposition.SWC_Secured.P_SecuredData, ecu-extract-reference=TopLevelCompositionPrototype.SWC_Secured.P_SecuredData
      CounterValue_127: upstream-reference=TopLevelComposition.SWC_Secured.P_SecuredData.CounterValue, ecu-extract-reference=TopLevelCompositionPrototype.SWC_Secured.P_SecuredData.CounterValue
      R_SecuredData_128: upstream-reference=TopLevelComposition.SWC_Secured.R_SecuredData, ecu-extract-reference=TopLevelCompositionPrototype.SWC_Secured.R_SecuredData
      CounterValue_129: upstream-reference=TopLevelComposition.SWC_Secured.R_SecuredData.CounterValue, ecu-extract-reference=TopLevelCompositionPrototype.SWC_Secured.R_SecuredData.CounterValue
      ServiceSwComponentSecOC_130: upstream-reference=TopLevelComposition.ServiceSwComponentSecOC, ecu-extract-reference=TopLevelCompositionPrototype.ServiceSwComponentSecOC
      PS_RxFreshnessManagement_131: upstream-reference=TopLevelComposition.ServiceSwComponentSecOC.PS_RxFreshnessManagement, ecu-extract-reference=TopLevelCompositionPrototype.ServiceSwComponentSecOC.PS_RxFreshnessManagement
      PS_TxFreshnessManagement_132: upstream-reference=TopLevelComposition.ServiceSwComponentSecOC.PS_TxFreshnessManagement, ecu-extract-reference=TopLevelCompositionPrototype.ServiceSwComponentSecOC.PS_TxFreshnessManagement
      ServiceSwComponentDem_133: upstream-reference=TopLevelComposition.ServiceSwComponentDem, ecu-extract-reference=TopLevelCompositionPrototype.ServiceSwComponentDem
      CBReadData_DemExternalCSDataElementClass_Session_134: upstream-reference=TopLevelComposition.ServiceSwComponentDem.CBReadData_DemExternalCSDataElementClass_Session, ecu-extract-reference=TopLevelCompositionPrototype.ServiceSwComponentDem.CBReadData_DemExternalCSDataElementClass_Session
      CBReadData_DemExternalCSDataElementClass_ExtDataRec_0x01_135: upstream-reference=TopLevelComposition.ServiceSwComponentDem.CBReadData_DemExternalCSDataElementClass_ExtDataRec_0x01, ecu-extract-reference=TopLevelCompositionPrototype.ServiceSwComponentDem.CBReadData_DemExternalCSDataElementClass_ExtDataRec_0x01
      SetClearDTC_master_136: upstream-reference=TopLevelComposition.ServiceSwComponentDem.SetClearDTC_master, ecu-extract-reference=TopLevelCompositionPrototype.ServiceSwComponentDem.SetClearDTC_master
